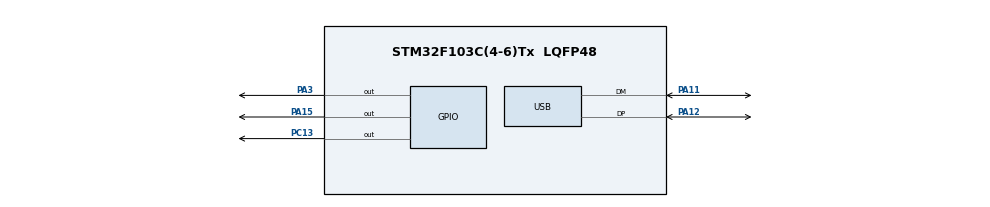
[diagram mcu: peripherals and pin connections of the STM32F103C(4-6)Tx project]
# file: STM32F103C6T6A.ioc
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Mcu.Family=STM32F1
Mcu.Name=STM32F103C(4-6)Tx
Mcu.Package=LQFP48
NVIC.PriorityGroup=NVIC_PRIORITYGROUP_4
NVIC.USB_LP_CAN1_RX0_IRQn=true\:0\:0\:false\:false\:true\:false\:true
PA11.Mode=Device
PA11.Signal=USB_DM
PA12.Mode=Device
PA12.Signal=USB_DP
PA13.Mode=Serial_Wire
PA13.Signal=SYS_JTMS-SWDIO
PA14.Mode=Serial_Wire
PA14.Signal=SYS_JTCK-SWCLK
PA15.Signal=GPIO_Output
PA3.Signal=GPIO_Output
PC13-TAMPER-RTC.Signal=GPIO_Output
PD0-OSC_IN.Mode=HSE-External-Oscillator
PD0-OSC_IN.Signal=RCC_OSC_IN
PD1-OSC_OUT.Mode=HSE-External-Oscillator
PD1-OSC_OUT.Signal=RCC_OSC_OUT
ProjectManager.HeapSize=0x200
ProjectManager.StackSize=0x400
ProjectManager.TargetToolchain=MDK-ARM V5.27
RCC.AHBFreq_Value=72000000
RCC.APB1CLKDivider=RCC_HCLK_DIV2
RCC.APB1Freq_Value=36000000
RCC.APB1TimFreq_Value=72000000
RCC.APB2Freq_Value=72000000
RCC.APB2TimFreq_Value=72000000
RCC.HCLKFreq_Value=72000000
RCC.PLLMUL=RCC_PLL_MUL9
RCC.SYSCLKFreq_VALUE=72000000
RCC.SYSCLKSource=RCC_SYSCLKSOURCE_PLLCLK
RCC.USBFreq_Value=48000000
RCC.USBPrescaler=RCC_USBCLKSOURCE_PLL_DIV1_5
USB_DEVICE.CLASS_NAME_FS=CDC
USB_DEVICE.VirtualMode=Cdc
USB_DEVICE.VirtualModeFS=Cdc_FS
VP_USB_DEVICE_VS_USB_DEVICE_CDC_FS.Mode=CDC_FS
board=custom

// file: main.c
/* USER CODE BEGIN Header */
/**
  ******************************************************************************
  * @file           : main.c
  * @brief          : Main program body
  ******************************************************************************
  * @attention
  *
  * <h2><center>&copy; Copyright (c) 2022 STMicroelectronics.
  * All rights reserved.</center></h2>
  *
  * This software component is licensed by ST under BSD 3-Clause license,
  * the "License"; You may not use this file except in compliance with the
  * License. You may obtain a copy of the License at:
  *                        opensource.org/licenses/BSD-3-Clause
  *
  ******************************************************************************
  */
/* USER CODE END Header */

#include "main.h"
#include "usb_device.h"

/* USER CODE BEGIN Includes */
#include "ADC.h"

/* USER CODE END Includes */

void SystemClock_Config(void);
static void MX_GPIO_Init(void);

int main(void)
{

  /* MCU Configuration--------------------------------------------------------*/

  /* Reset of all peripherals, Initializes the Flash interface and the Systick. */
  HAL_Init();

  /* Configure the system clock */
  SystemClock_Config();

  /* Initialize all configured peripherals */
  MX_GPIO_Init();
  MX_USB_DEVICE_Init();

  /* Infinite loop */
  /* USER CODE BEGIN WHILE */
	InitADC();
	InitTimer();
	InitDMA();

  while (1)
  {
    /* USER CODE END WHILE */

    /* USER CODE BEGIN 3 */

			LL_GPIO_SetOutputPin(GPIOA, LL_GPIO_PIN_3);
			LL_mDelay(1000);
			LL_GPIO_ResetOutputPin(GPIOA, LL_GPIO_PIN_3);

			LL_GPIO_SetOutputPin(GPIOA, LL_GPIO_PIN_15);
			LL_mDelay(1000);
			LL_GPIO_ResetOutputPin(GPIOA, LL_GPIO_PIN_15);

			LL_GPIO_SetOutputPin(GPIOC, LL_GPIO_PIN_13);
			LL_mDelay(1000);
			LL_GPIO_ResetOutputPin(GPIOC, LL_GPIO_PIN_13);

  }
  /* USER CODE END 3 */
}

void SystemClock_Config(void)
{
  LL_FLASH_SetLatency(LL_FLASH_LATENCY_2);

   if(LL_FLASH_GetLatency() != LL_FLASH_LATENCY_2)
  {
    Error_Handler();
  }
  LL_RCC_HSE_Enable();

   /* Wait till HSE is ready */
  while(LL_RCC_HSE_IsReady() != 1)
  {

  }
  LL_RCC_PLL_ConfigDomain_SYS(LL_RCC_PLLSOURCE_HSE_DIV_1, LL_RCC_PLL_MUL_9);
  LL_RCC_PLL_Enable();

   /* Wait till PLL is ready */
  while(LL_RCC_PLL_IsReady() != 1)
  {

  }
  LL_RCC_SetAHBPrescaler(LL_RCC_SYSCLK_DIV_1);
  LL_RCC_SetAPB1Prescaler(LL_RCC_APB1_DIV_2);
  LL_RCC_SetAPB2Prescaler(LL_RCC_APB2_DIV_1);
  LL_RCC_SetSysClkSource(LL_RCC_SYS_CLKSOURCE_PLL);

   /* Wait till System clock is ready */
  while(LL_RCC_GetSysClkSource() != LL_RCC_SYS_CLKSOURCE_STATUS_PLL)
  {

  }
  LL_SetSystemCoreClock(72000000);

   /* Update the time base */
  if (HAL_InitTick (TICK_INT_PRIORITY) != HAL_OK)
  {
    Error_Handler();
  };
  LL_RCC_SetUSBClockSource(LL_RCC_USB_CLKSOURCE_PLL_DIV_1_5);
}

static void MX_GPIO_Init(void)
{
  LL_GPIO_InitTypeDef GPIO_InitStruct = {0};

  /* GPIO Ports Clock Enable */
  LL_APB2_GRP1_EnableClock(LL_APB2_GRP1_PERIPH_GPIOC);
  LL_APB2_GRP1_EnableClock(LL_APB2_GRP1_PERIPH_GPIOD);
  LL_APB2_GRP1_EnableClock(LL_APB2_GRP1_PERIPH_GPIOA);

  /**/
  LL_GPIO_ResetOutputPin(GPIOC, LL_GPIO_PIN_13);

  /**/
  LL_GPIO_ResetOutputPin(GPIOA, LL_GPIO_PIN_3|LL_GPIO_PIN_15);

  /**/
  GPIO_InitStruct.Pin = LL_GPIO_PIN_13;
  GPIO_InitStruct.Mode = LL_GPIO_MODE_OUTPUT;
  GPIO_InitStruct.Speed = LL_GPIO_SPEED_FREQ_LOW;
  GPIO_InitStruct.OutputType = LL_GPIO_OUTPUT_PUSHPULL;
  LL_GPIO_Init(GPIOC, &GPIO_InitStruct);

  /**/
  GPIO_InitStruct.Pin = LL_GPIO_PIN_3|LL_GPIO_PIN_15;
  GPIO_InitStruct.Mode = LL_GPIO_MODE_OUTPUT;
  GPIO_InitStruct.Speed = LL_GPIO_SPEED_FREQ_LOW;
  GPIO_InitStruct.OutputType = LL_GPIO_OUTPUT_PUSHPULL;
  LL_GPIO_Init(GPIOA, &GPIO_InitStruct);

}

void Error_Handler(void)
{
}

/************************ (C) COPYRIGHT STMicroelectronics *****END OF FILE****/
